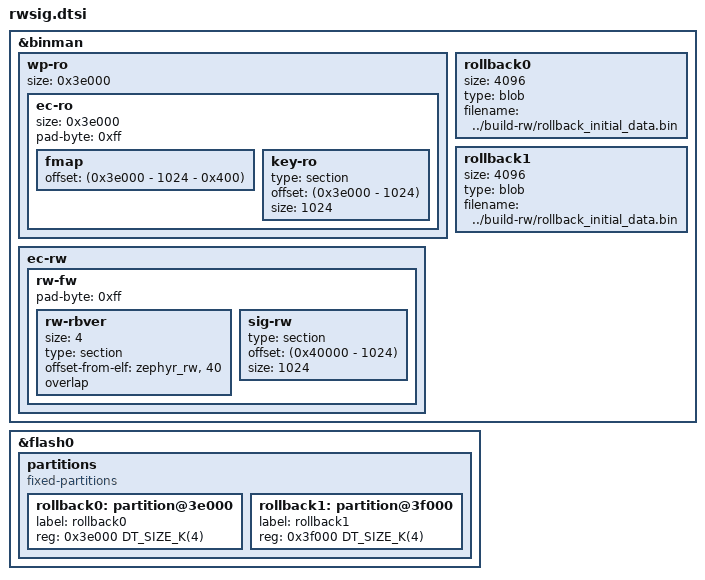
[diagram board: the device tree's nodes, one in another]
/* Copyright 2023 The ChromiumOS Authors
 * Use of this source code is governed by a BSD-style license that can be
 * found in the LICENSE file.
 */

#include <cros/integrated_fwid.dtsi>

&binman {
	wp-ro {
		size = <0x3e000>;

		ec-ro {
			size = <0x3e000>;

			fmap {
				offset = <(0x3e000 - 1024 - 0x400)>;
				/*
				 * don't specify 'size = <0x400>' here so
				 * it is auto-assigned to the fmap size.
				 */
			};
			key-ro {
				type = "section";
				offset = <(0x3e000 - 1024)>;
				size = <1024>;
			};
			pad-byte = <0xff>;
		};

		/delete-node/ pstate;
	};

	rollback0 {
		size = <4096>;
		type = "blob";
		filename = "../build-rw/rollback_initial_data.bin";
	};

	rollback1 {
		size = <4096>;
		type = "blob";
		filename = "../build-rw/rollback_initial_data.bin";
	};

	ec-rw {
		rw-fw {
			rw-rbver {
				size = <4>;
				type = "section";
				/* points to
				 * current_image_data.rollback_version
				 */
				offset-from-elf = <&zephyr_rw>,
					"current_image_data", <40>;
				overlap;
			};

			sig-rw {
				type = "section";
				offset = <(0x40000 - 1024)>;
				size = <1024>;
			};

			/* rwsig assumes the padding bytes between zephyr-rw and
			 * sig-rw are filled with 0xff.
			 */
			pad-byte = <0xff>;
		};
	};
};

&flash0 {
	partitions {
		compatible = "fixed-partitions";
		#address-cells = <1>;
		#size-cells = <1>;

		rollback0: partition@3e000 {
			label = "rollback0";
			reg = <0x3e000 DT_SIZE_K(4)>;
		};

		rollback1: partition@3f000 {
			label = "rollback1";
			reg = <0x3f000 DT_SIZE_K(4)>;
		};
	};
};
